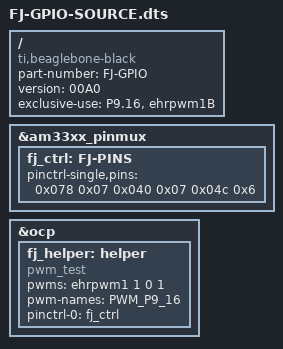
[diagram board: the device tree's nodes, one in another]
/*  
* Based on DTS by Texas Instruments Incorporated - http://www.ti.com/
* Copyright (C) 2013, Tobias Janke - http://www.fj-computertechnik.de
*/

/dts-v1/;
/plugin/;

/ {
       compatible = "ti,beaglebone-black";
       part-number = "FJ-GPIO";
       version = "00A0";
       exclusive-use = "P9.16",	"ehrpwm1B";

       fragment@0 {
             target = <&am33xx_pinmux>;
            
             __overlay__ {
                  fj_ctrl: FJ-PINS {
			pinctrl-single,pins = <
				0x078 0x07
				0x040 0x07
				0x04c 0x6
			>;
		  };
		  
             };
       };

       fragment@1 {
		target = <&ocp>;
		__overlay__ {
			fj_helper: helper {
				compatible	= "pwm_test";
				pwms 		= <&ehrpwm1 1 0 1>;
				pwm-names 	= "PWM_P9_16";

				pinctrl-names	= "default";
				pinctrl-0	= <&fj_ctrl>;

				status 		= "okay";
			};
		};
	};
};
